# ATxmega256A3BU device description
Architecture: AVR8_XMEGA; Family: AVR XMEGA
Registers are 8-bit, access not given, no defined reset value unless marked. A register's access mark holds for its fields unless they carry their own. Offsets are from the block's base; [hi:lo] are bit positions; {n}, {i} and the like mark numbered series; 'fields as' and 'values as' point back to an identical list.

## USB — Universal Serial Bus
Instances: USB 0x4C0
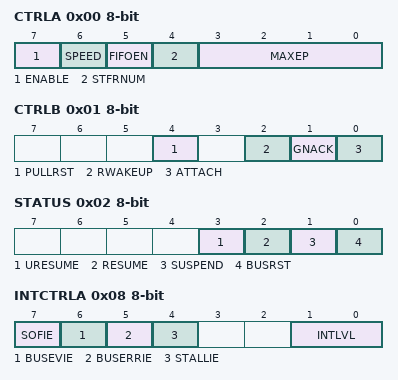
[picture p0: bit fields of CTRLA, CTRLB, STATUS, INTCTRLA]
0x00 CTRLA — Control Register A
  [7] ENABLE — USB Enable
  [6] SPEED — Speed Select
  [5] FIFOEN — USB FIFO Enable
  [4] STFRNUM — Store Frame Number Enable
  [3:0] MAXEP — Maximum Endpoint Addresses
0x01 CTRLB — Control Register B
  [4] PULLRST — Pull during Reset
  [2] RWAKEUP — Remote Wake-up
  [1] GNACK — Global NACK
  [0] ATTACH
0x02 STATUS
  [3] URESUME — Upstream Resume
  [2] RESUME
  [1] SUSPEND — Bus Suspended
  [0] BUSRST — Bus Reset
0x03 ADDR — Address Register
  [6:0] ADDR — Device Address
0x04 FIFOWP — FIFO Write Pointer Register
  [4:0] FIFOWP — FIFO Write Pointer
0x05 FIFORP — FIFO Read Pointer Register
  [4:0] FIFORP — FIFO Read Pointer
0x06 EPPTR 16-bit — Endpoint Configuration Table Pointer
0x08 INTCTRLA — Interrupt Control Register A
  [7] SOFIE — Start Of Frame Interrupt Enable
  [6] BUSEVIE — Bus Event Interrupt Enable
  [5] BUSERRIE — Bus Error Interrupt Enable
  [4] STALLIE — STALL Interrupt Enable
  [1:0] INTLVL — Interrupt Level
    0=OFF (Interrupt disabled); 1=LO (Low level); 2=MED (Medium level); 3=HI (High level)
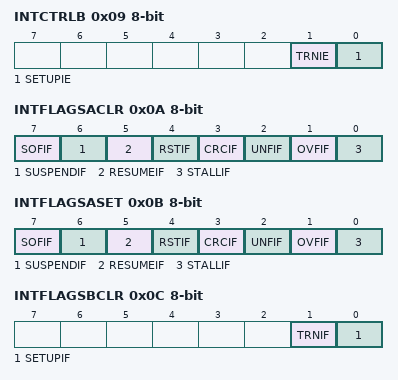
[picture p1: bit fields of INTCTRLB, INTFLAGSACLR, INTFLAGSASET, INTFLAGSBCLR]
0x09 INTCTRLB — Interrupt Control Register B
  [1] TRNIE — Transaction Complete Interrupt Enable
  [0] SETUPIE — SETUP Transaction Complete Interrupt Enable
0x0A INTFLAGSACLR — Clear Interrupt Flag Register A
  [7] SOFIF — Start Of Frame Interrupt Flag
  [6] SUSPENDIF — Suspend Interrupt Flag
  [5] RESUMEIF — Resume Interrupt Flag
  [4] RSTIF — Reset Interrupt Flag
  [3] CRCIF — Isochronous CRC Error Interrupt Flag
  [2] UNFIF — Underflow Interrupt Flag
  [1] OVFIF — Overflow Interrupt Flag
  [0] STALLIF — STALL Interrupt Flag
0x0B INTFLAGSASET — Set Interrupt Flag Register A
  fields as INTFLAGSACLR
0x0C INTFLAGSBCLR — Clear Interrupt Flag Register B
  [1] TRNIF — Transaction Complete Interrupt Flag
  [0] SETUPIF — SETUP Transaction Complete Interrupt Flag
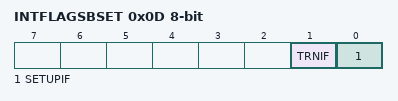
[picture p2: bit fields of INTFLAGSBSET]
0x0D INTFLAGSBSET — Set Interrupt Flag Register B
  fields as INTFLAGSBCLR
0x3A CAL0 — Calibration Byte 0
0x3B CAL1 — Calibration Byte 1

## USB_EP_TABLE — USB Endpoint Table
0x110 FRAMENUML — Frame Number Low Byte
0x111 FRAMENUMH — Frame Number High Byte

## PORT — I/O Ports
Instances: PORTA 0x0600, PORTB 0x0620, PORTC 0x0640, PORTD 0x0660, PORTE 0x0680, PORTF 0x06A0, PORTR 0x07E0
0x00 DIR — I/O Port Data Direction
0x01 DIRSET — I/O Port Data Direction Set
0x02 DIRCLR — I/O Port Data Direction Clear
0x03 DIRTGL — I/O Port Data Direction Toggle
0x04 OUT — I/O Port Output
0x05 OUTSET — I/O Port Output Set
0x06 OUTCLR — I/O Port Output Clear
0x07 OUTTGL — I/O Port Output Toggle
0x08 IN — I/O port Input
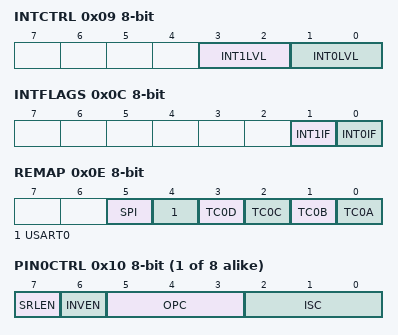
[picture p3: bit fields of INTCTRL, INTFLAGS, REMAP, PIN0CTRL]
0x09 INTCTRL — Interrupt Control Register
  [3:2] INT1LVL — Port Interrupt 1 Level
    0=OFF (Interrupt Disabled); 1=LO (Low Level); 2=MED (Medium Level); 3=HI (High Level)
  [1:0] INT0LVL — Port Interrupt 0 Level
    values as INT1LVL
0x0A INT0MASK — Port Interrupt 0 Mask
0x0B INT1MASK — Port Interrupt 1 Mask
0x0C INTFLAGS — Interrupt Flag Register
  [1] INT1IF — Port Interrupt 1 Flag
  [0] INT0IF — Port Interrupt 0 Flag
0x0E REMAP — I/O Port Pin Remap Register
  [5] SPI
  [4] USART0
  [3] TC0D — Timer/Counter 0 Output Compare D
  [2] TC0C — Timer/Counter 0 Output Compare C
  [1] TC0B — Timer/Counter 0 Output Compare B
  [0] TC0A — Timer/Counter 0 Output Compare A
{0x10+i} PIN{i}CTRL (i=0..7) — Pin {i} Control Register
  [7] SRLEN — Slew Rate Enable
  [6] INVEN — Inverted I/O Enable
  [5:3] OPC — Output/Pull Configuration
    0=TOTEM (Totempole); 1=BUSKEEPER (Totempole w/ Bus keeper on Input and Output); 2=PULLDOWN (Totempole w/ Pull-down on Input); 3=PULLUP (Totempole w/ Pull-up on Input); 4=WIREDOR; 5=WIREDAND; 6=WIREDORPULL (Wired OR w/ Pull-down); 7=WIREDANDPULL (Wired AND w/ Pull-up)
  [2:0] ISC — Input/Sense Configuration
    0=BOTHEDGES (Sense Both Edges); 1=RISING (Sense Rising Edge); 2=FALLING (Sense Falling Edge); 3=LEVEL (Sense Level (Transparent For Events)); 7=INPUT_DISABLE (Disable Digital Input Buffer)
